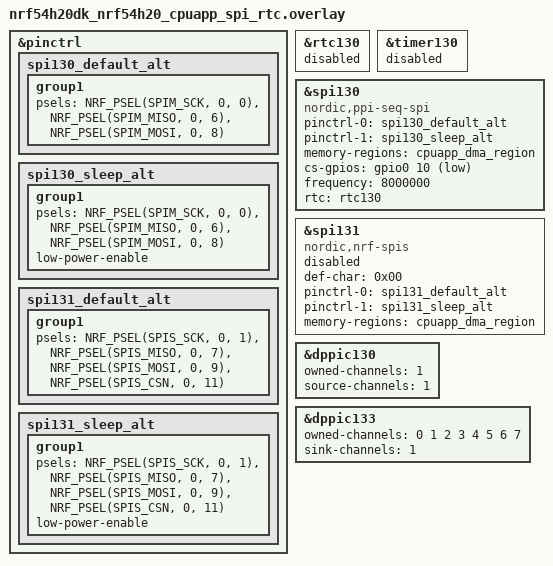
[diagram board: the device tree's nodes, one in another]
/*
 * Copyright (c) 2026 Nordic Semiconductor ASA
 *
 * SPDX-License-Identifier: LicenseRef-Nordic-5-Clause
 */

/* Test requires loopbacks:
 * - between P1.11 and P1.10.
 * - between P1.12 and P1.13,
 */

&pinctrl {
	spi130_default_alt: spi130_default_alt {
		group1 {
			psels = <NRF_PSEL(SPIM_SCK, 0, 0)>,
				<NRF_PSEL(SPIM_MISO, 0, 6)>,
				<NRF_PSEL(SPIM_MOSI, 0, 8)>;
		};
	};

	spi130_sleep_alt: spi130_sleep_alt {
		group1 {
			psels = <NRF_PSEL(SPIM_SCK, 0, 0)>,
				<NRF_PSEL(SPIM_MISO, 0, 6)>,
				<NRF_PSEL(SPIM_MOSI, 0, 8)>;
			low-power-enable;
		};
	};

	spi131_default_alt: spi131_default_alt {
		group1 {
			psels = <NRF_PSEL(SPIS_SCK, 0, 1)>,
				<NRF_PSEL(SPIS_MISO, 0, 7)>,
				<NRF_PSEL(SPIS_MOSI, 0, 9)>,
				<NRF_PSEL(SPIS_CSN, 0, 11)>;
		};
	};

	spi131_sleep_alt: spi131_sleep_alt {
		group1 {
			psels = <NRF_PSEL(SPIS_SCK, 0, 1)>,
				<NRF_PSEL(SPIS_MISO, 0, 7)>,
				<NRF_PSEL(SPIS_MOSI, 0, 9)>,
				<NRF_PSEL(SPIS_CSN, 0, 11)>;
			low-power-enable;
		};
	};
};

/* Used as trigger by the PPI sequencer. */
&rtc130 {
	status = "reserved";
};

test_timer: &timer130 {
	status = "reserved";
};

dut: &spi130 {
	compatible = "nordic,ppi-seq-spi";
	status = "okay";
	pinctrl-0 = <&spi130_default_alt>;
	pinctrl-1 = <&spi130_sleep_alt>;
	pinctrl-names = "default", "sleep";
	memory-regions = <&cpuapp_dma_region>;
	cs-gpios = <&gpio0 10 GPIO_ACTIVE_LOW>;
	frequency = <8000000>;
	rtc = <&rtc130>;
};

tester: &spi131 {
	compatible = "nordic,nrf-spis";
	status = "reserved";
	def-char = <0x00>;
	pinctrl-0 = <&spi131_default_alt>;
	pinctrl-1 = <&spi131_sleep_alt>;
	pinctrl-names = "default", "sleep";
	memory-regions = <&cpuapp_dma_region>;
	/delete-property/ rx-delay-supported;
	/delete-property/ rx-delay;
};

&dppic130 {
	status = "okay";

	owned-channels = <1>;
	source-channels = <1>;
};

&dppic133 {
	status = "okay";

	owned-channels = <0 1 2 3 4 5 6 7>;
	sink-channels = <1>;
};
